# STM32F765BGT6 register map
File version: 1.0
Registers are 32-bit, access not given, reset 0x0 unless marked. A register's access mark holds for its fields unless they carry their own. Offsets are from the block's base; [hi:lo] are bit positions; {n}, {i} and the like mark numbered series; 'fields as' and 'values as' point back to an identical list.

## ADC1
Base 0x40012000
Same registers: ADC2 0x40012100, ADC3 0x40012300
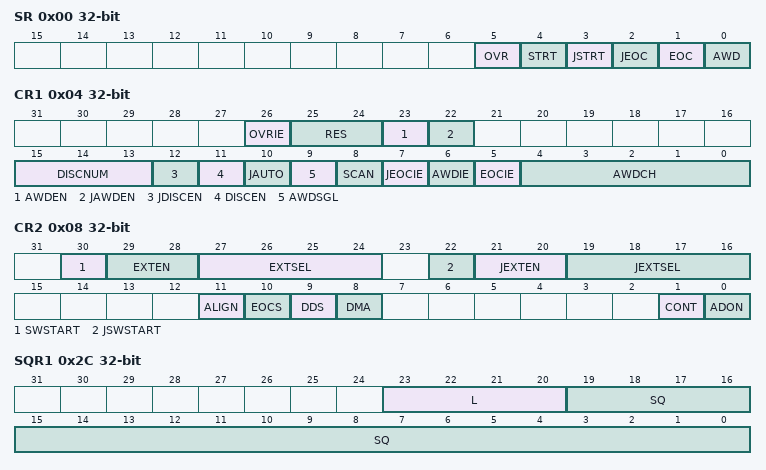
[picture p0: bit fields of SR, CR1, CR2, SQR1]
0x00 SR
  [5] OVR, [4] STRT, [3] JSTRT, [2] JEOC, [1] EOC, [0] AWD
0x04 CR1
  [26] OVRIE, [25:24] RES, [23] AWDEN, [22] JAWDEN, [15:13] DISCNUM, [12] JDISCEN, [11] DISCEN, [10] JAUTO, [9] AWDSGL, [8] SCAN, [7] JEOCIE, [6] AWDIE, [5] EOCIE, [4:0] AWDCH
0x08 CR2
  [30] SWSTART, [29:28] EXTEN, [27:24] EXTSEL, [22] JSWSTART, [21:20] JEXTEN, [19:16] JEXTSEL, [11] ALIGN, [10] EOCS, [9] DDS, [8] DMA, [1] CONT, [0] ADON
0x0C SMPR1
  [31:0] SMP
0x10 SMPR2
  [31:0] SMP
{0x10+4i} JOFR{i} (i=1..4)
  [11:0] JOFFSET{i}
0x24 HTR
  [11:0] HT
0x28 LTR
  [11:0] LT
0x2C SQR1
  [23:20] L, [19:0] SQ
0x30 SQR2
  [29:0] SQ
0x34 SQR3
  [29:0] SQ
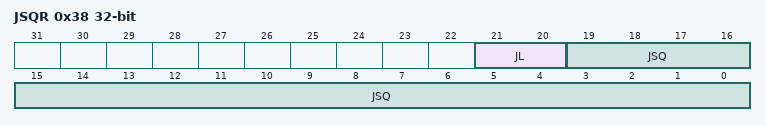
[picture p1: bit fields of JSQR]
0x38 JSQR
  [21:20] JL, [19:0] JSQ
{0x38+4i} JDR{i} (i=1..4)
  [15:0] JDATA
0x4C DR
  [15:0] DATA

## SYSCFG
Base 0x40013800
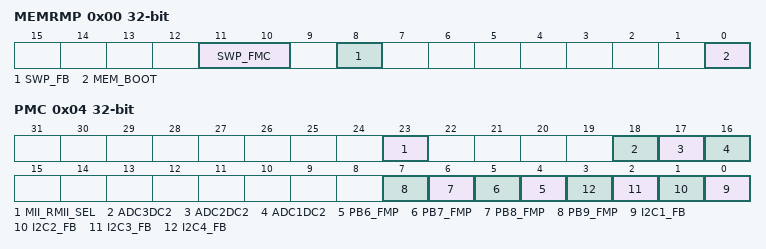
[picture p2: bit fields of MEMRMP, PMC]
0x00 MEMRMP
  [11:10] SWP_FMC, [8] SWP_FB, [0] MEM_BOOT
0x04 PMC
  [23] MII_RMII_SEL, [18] ADC3DC2, [17] ADC2DC2, [16] ADC1DC2, [n-2] PB{n}_FMP (n=6..9), [n-1] I2C{n}_FB (n=1..4)
{0x4+4i} EXTICR{i} (i=1..4)
0x1C CBR
0x20 CMPCR

## EXTI
Base 0x40013C00
0x00 IMR
0x04 EMR
0x08 RTSR
0x0C FTSR
0x10 SWIER
0x14 PR

## SAI1
Base 0x40015800
Same registers: SAI2 0x40015C00
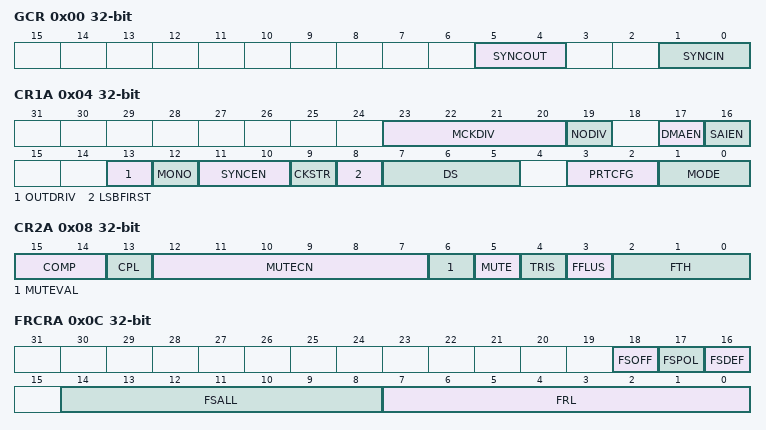
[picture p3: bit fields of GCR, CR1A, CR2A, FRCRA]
0x00 GCR
  [5:4] SYNCOUT, [1:0] SYNCIN
0x04 CR1A
  [23:20] MCKDIV, [19] NODIV, [17] DMAEN, [16] SAIEN, [13] OUTDRIV, [12] MONO, [11:10] SYNCEN, [9] CKSTR, [8] LSBFIRST, [7:5] DS, [3:2] PRTCFG, [1:0] MODE
0x08 CR2A
  [15:14] COMP, [13] CPL, [12:7] MUTECN, [6] MUTEVAL, [5] MUTE, [4] TRIS, [3] FFLUS, [2:0] FTH
0x0C FRCRA
  [18] FSOFF, [17] FSPOL, [16] FSDEF, [14:8] FSALL, [7:0] FRL
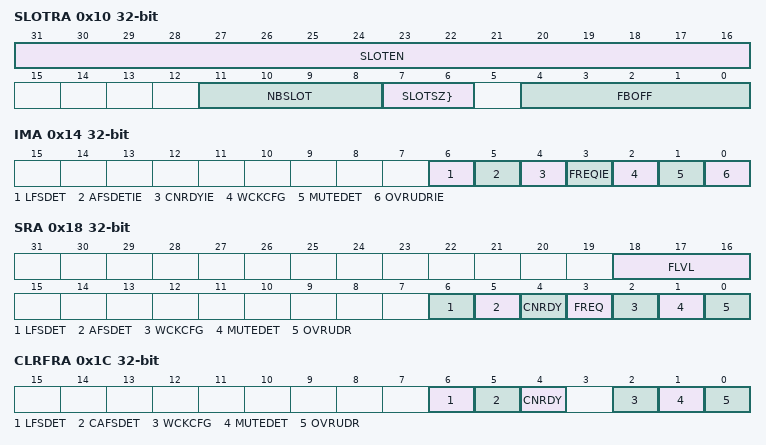
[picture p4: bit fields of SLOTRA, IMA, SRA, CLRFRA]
0x10 SLOTRA
  [31:16] SLOTEN, [11:8] NBSLOT, [7:6] SLOTSZ}, [4:0] FBOFF
0x14 IMA
  [6] LFSDET, [5] AFSDETIE, [4] CNRDYIE, [3] FREQIE, [2] WCKCFG, [1] MUTEDET, [0] OVRUDRIE
0x18 SRA
  [18:16] FLVL, [6] LFSDET, [5] AFSDET, [4] CNRDY, [3] FREQ, [2] WCKCFG, [1] MUTEDET, [0] OVRUDR
0x1C CLRFRA
  [6] LFSDET, [5] CAFSDET, [4] CNRDY, [2] WCKCFG, [1] MUTEDET, [0] OVRUDR
0x20 DRA
  [31:0] DATA
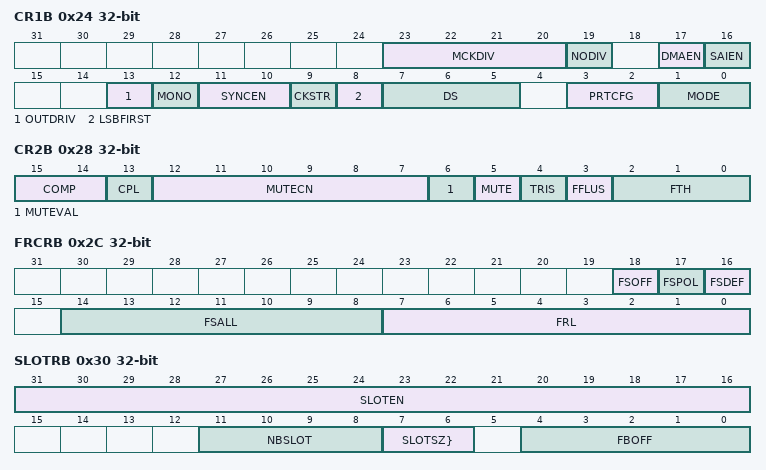
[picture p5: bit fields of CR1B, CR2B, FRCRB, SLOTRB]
0x24 CR1B
  fields as CR1A
0x28 CR2B
  fields as CR2A
0x2C FRCRB
  [18] FSOFF, [17] FSPOL, [16] FSDEF, [14:8] FSALL, [7:0] FRL
0x30 SLOTRB
  [31:16] SLOTEN, [11:8] NBSLOT, [7:6] SLOTSZ}, [4:0] FBOFF
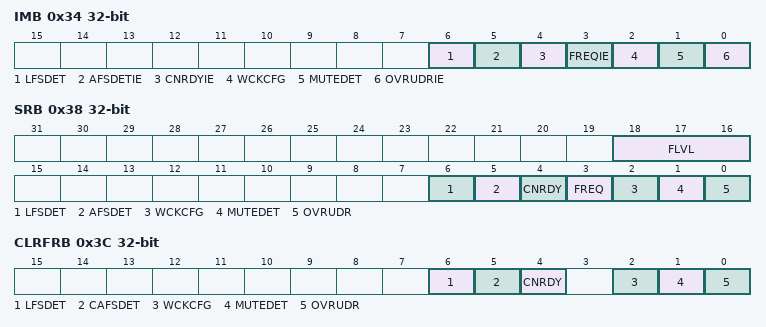
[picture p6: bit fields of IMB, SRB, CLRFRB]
0x34 IMB
  fields as IMA
0x38 SRB
  fields as SRA
0x3C CLRFRB
  fields as CLRFRA
0x40 DRB
  [31:0] DATA

## LTDC
Base 0x40016800
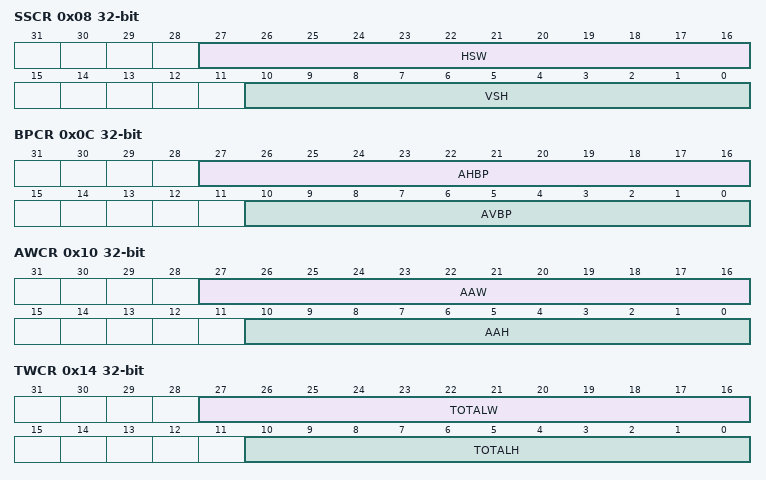
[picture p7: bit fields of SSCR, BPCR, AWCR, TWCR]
0x08 SSCR
  [27:16] HSW, [10:0] VSH
0x0C BPCR
  [27:16] AHBP, [10:0] AVBP
0x10 AWCR
  [27:16] AAW, [10:0] AAH
0x14 TWCR
  [27:16] TOTALW, [10:0] TOTALH
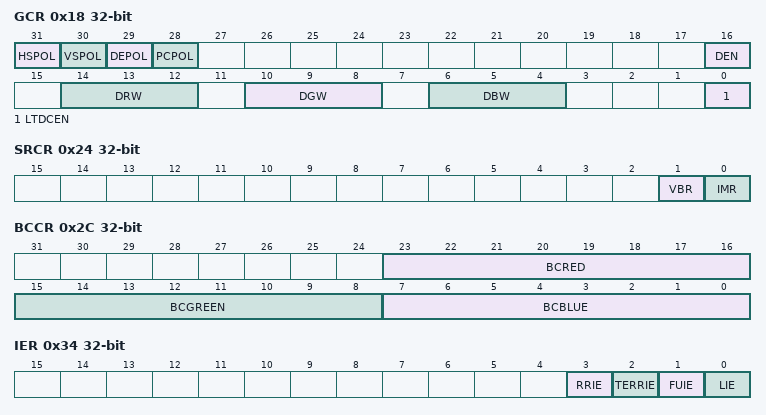
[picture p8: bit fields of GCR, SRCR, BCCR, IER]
0x18 GCR
  [31] HSPOL, [30] VSPOL, [29] DEPOL, [28] PCPOL, [16] DEN, [14:12] DRW, [10:8] DGW, [6:4] DBW, [0] LTDCEN
0x24 SRCR
  [1] VBR, [0] IMR
0x2C BCCR
  [23:16] BCRED, [15:8] BCGREEN, [7:0] BCBLUE
0x34 IER
  [3] RRIE, [2] TERRIE, [1] FUIE, [0] LIE
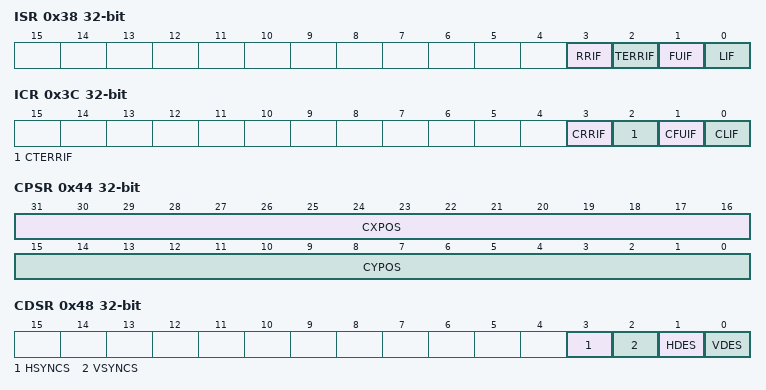
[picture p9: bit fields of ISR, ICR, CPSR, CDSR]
0x38 ISR
  [3] RRIF, [2] TERRIF, [1] FUIF, [0] LIF
0x3C ICR
  [3] CRRIF, [2] CTERRIF, [1] CFUIF, [0] CLIF
0x40 LIPCR
  [10:0] LIPOS
0x44 CPSR
  [31:16] CXPOS, [15:0] CYPOS
0x48 CDSR
  [3] HSYNCS, [2] VSYNCS, [1] HDES, [0] VDES
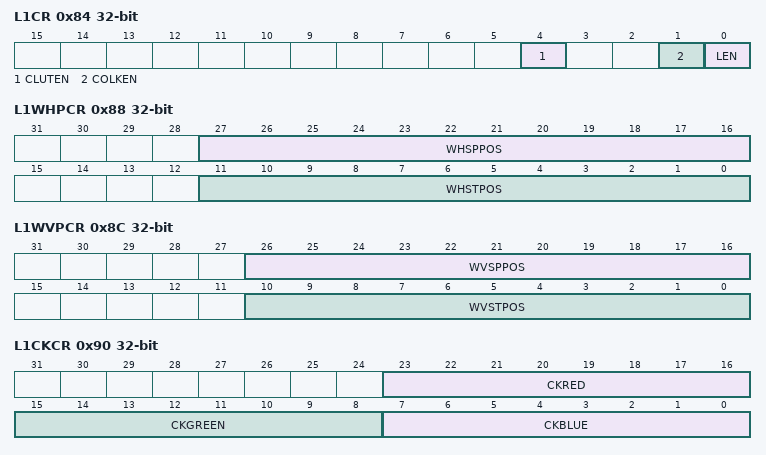
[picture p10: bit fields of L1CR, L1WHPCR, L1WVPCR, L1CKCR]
0x84 L1CR
  [4] CLUTEN, [1] COLKEN, [0] LEN
0x88 L1WHPCR
  [27:16] WHSPPOS, [11:0] WHSTPOS
0x8C L1WVPCR
  [26:16] WVSPPOS, [10:0] WVSTPOS
0x90 L1CKCR
  [23:16] CKRED, [15:8] CKGREEN, [7:0] CKBLUE
0x94 L1PFCR
  [2:0] PF
0x98 L1CACR
  [7:0] CONSTA
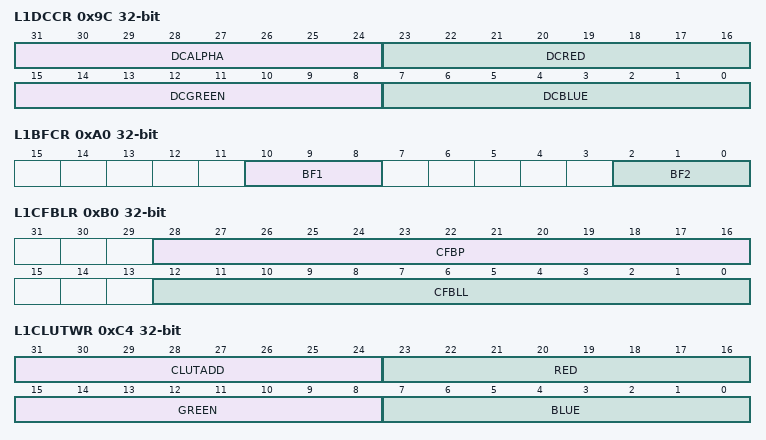
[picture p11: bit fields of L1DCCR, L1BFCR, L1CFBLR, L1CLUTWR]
0x9C L1DCCR
  [31:24] DCALPHA, [23:16] DCRED, [15:8] DCGREEN, [7:0] DCBLUE
0xA0 L1BFCR
  [10:8] BF1, [2:0] BF2
0xAC L1CFBAR
  [31:0] CFBADD
0xB0 L1CFBLR
  [28:16] CFBP, [12:0] CFBLL
0xB4 L1CFBLNR
  [10:0] CFBLNBR
0xC4 L1CLUTWR
  [31:24] CLUTADD, [23:16] RED, [15:8] GREEN, [7:0] BLUE
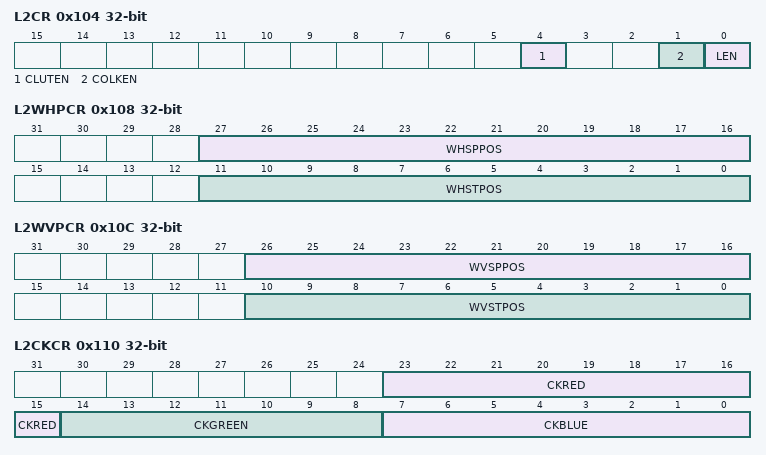
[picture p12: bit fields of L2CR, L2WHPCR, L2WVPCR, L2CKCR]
0x104 L2CR
  [4] CLUTEN, [1] COLKEN, [0] LEN
0x108 L2WHPCR
  [27:16] WHSPPOS, [11:0] WHSTPOS
0x10C L2WVPCR
  [26:16] WVSPPOS, [10:0] WVSTPOS
0x110 L2CKCR
  [23:15] CKRED, [14:8] CKGREEN, [7:0] CKBLUE
0x114 L2PFCR
  [2:0] PF
0x118 L2CACR
  [7:0] CONSTA
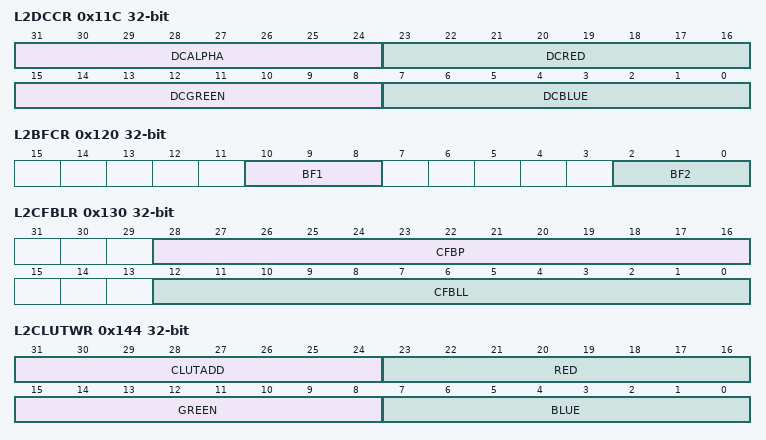
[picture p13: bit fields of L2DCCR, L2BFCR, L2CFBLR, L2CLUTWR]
0x11C L2DCCR
  [31:24] DCALPHA, [23:16] DCRED, [15:8] DCGREEN, [7:0] DCBLUE
0x120 L2BFCR
  [10:8] BF1, [2:0] BF2
0x12C L2CFBAR
  [31:0] CFBADD
0x130 L2CFBLR
  [28:16] CFBP, [12:0] CFBLL
0x134 L2CFBLNR
  [10:0] CFBLNBR
0x144 L2CLUTWR
  [31:24] CLUTADD, [23:16] RED, [15:8] GREEN, [7:0] BLUE
